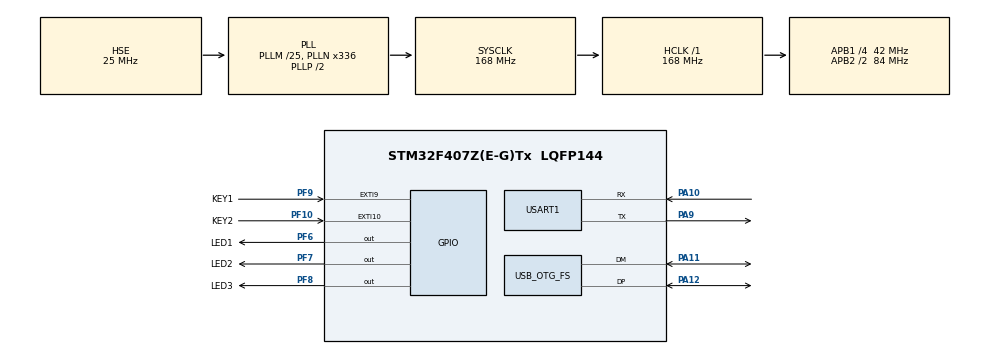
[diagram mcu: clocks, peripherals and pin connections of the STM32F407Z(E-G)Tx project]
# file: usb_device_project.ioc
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Mcu.Family=STM32F4
Mcu.Name=STM32F407Z(E-G)Tx
Mcu.Package=LQFP144
NVIC.EXTI15_10_IRQn=true\:0\:0\:false\:false\:true\:true\:true\:true
NVIC.EXTI9_5_IRQn=true\:0\:0\:false\:false\:true\:true\:true\:true
NVIC.OTG_FS_IRQn=true\:0\:0\:false\:false\:true\:false\:true\:true
NVIC.PriorityGroup=NVIC_PRIORITYGROUP_4
PA10.Mode=Asynchronous
PA10.Signal=USART1_RX
PA11.Mode=Device_Only
PA11.Signal=USB_OTG_FS_DM
PA12.Mode=Device_Only
PA12.Signal=USB_OTG_FS_DP
PA9.Mode=Asynchronous
PA9.Signal=USART1_TX
PF10.GPIO_Label=KEY2
PF10.GPIO_ModeDefaultEXTI=GPIO_MODE_IT_RISING_FALLING
PF10.GPIO_PuPd=GPIO_PULLUP
PF10.Signal=GPXTI10
PF6.GPIO_Label=LED1
PF6.PinState=GPIO_PIN_SET
PF6.Signal=GPIO_Output
PF7.GPIO_Label=LED2
PF7.PinState=GPIO_PIN_SET
PF7.Signal=GPIO_Output
PF8.GPIO_Label=LED3
PF8.PinState=GPIO_PIN_SET
PF8.Signal=GPIO_Output
PF9.GPIO_Label=KEY1
PF9.GPIO_ModeDefaultEXTI=GPIO_MODE_IT_RISING_FALLING
PF9.GPIO_PuPd=GPIO_PULLUP
PF9.Signal=GPXTI9
PH0-OSC_IN.Mode=HSE-External-Oscillator
PH0-OSC_IN.Signal=RCC_OSC_IN
PH1-OSC_OUT.Mode=HSE-External-Oscillator
PH1-OSC_OUT.Signal=RCC_OSC_OUT
ProjectManager.HeapSize=0x200
ProjectManager.StackSize=0x400
ProjectManager.TargetToolchain=STM32CubeIDE
RCC.48MHZClocksFreq_Value=48000000
RCC.AHBFreq_Value=168000000
RCC.APB1CLKDivider=RCC_HCLK_DIV4
RCC.APB1Freq_Value=42000000
RCC.APB1TimFreq_Value=84000000
RCC.APB2CLKDivider=RCC_HCLK_DIV2
RCC.APB2Freq_Value=84000000
RCC.APB2TimFreq_Value=168000000
RCC.CortexFreq_Value=168000000
RCC.HCLKFreq_Value=168000000
RCC.HSE_VALUE=25000000
RCC.HSI_VALUE=16000000
RCC.LSE_VALUE=32768
RCC.PLLM=25
RCC.PLLN=336
RCC.PLLQ=7
RCC.SYSCLKFreq_VALUE=168000000
RCC.SYSCLKSource=RCC_SYSCLKSOURCE_PLLCLK
RCC.VCOOutputFreq_Value=336000000
USART1.VirtualMode=VM_ASYNC
USB_DEVICE.CLASS_NAME_FS=CUSTOM_HID
USB_DEVICE.USBD_CUSTOMHID_OUTREPORT_BUF_SIZE-CUSTOM_HID_FS=2
USB_DEVICE.USBD_CUSTOM_HID_REPORT_DESC_SIZE-CUSTOM_HID_FS=163
USB_DEVICE.VirtualMode-CUSTOM_HID_FS=CustomHid
USB_DEVICE.VirtualModeFS=Custom_Hid_FS
USB_OTG_FS.VirtualMode=Device_Only
VP_USB_DEVICE_VS_USB_DEVICE_CUSTOM_HID_FS.Mode=CUSTOM_HID_FS
board=custom

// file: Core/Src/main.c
/* USER CODE BEGIN Header */
/**
  ******************************************************************************
  * @file           : main.c
  * @brief          : Main program body
  ******************************************************************************
  * @attention
  *
  * Copyright (c) 2026 STMicroelectronics.
  * All rights reserved.
  *
  * This software is licensed under terms that can be found in the LICENSE file
  * in the root directory of this software component.
  * If no LICENSE file comes with this software, it is provided AS-IS.
  *
  ******************************************************************************
  */
/* USER CODE END Header */
#include "main.h"
#include "usb_device.h"

UART_HandleTypeDef huart1;

void SystemClock_Config(void);
static void MX_GPIO_Init(void);
static void MX_USART1_UART_Init(void);

/* USER CODE BEGIN 0 */
#define hUART           huart1
int _write( int32_t file , uint8_t *ptr , int32_t len )
{
    /* Implement your write code here, this is used by puts and printf for example */
    for ( int16_t i = 0 ; i < len ; ++i )
    {
        HAL_UART_Transmit( &hUART, ptr++, 1, 100);
    }
    return len;
}
/* USER CODE END 0 */

int main(void)
{

  /* MCU Configuration--------------------------------------------------------*/

  /* Reset of all peripherals, Initializes the Flash interface and the Systick. */
  HAL_Init();

  /* Configure the system clock */
  SystemClock_Config();

  /* Initialize all configured peripherals */
  MX_GPIO_Init();
  MX_USART1_UART_Init();
  MX_USB_DEVICE_Init();

  /* Infinite loop */
  while (1)
  {

  }
}

void SystemClock_Config(void)
{
  RCC_OscInitTypeDef RCC_OscInitStruct = {0};
  RCC_ClkInitTypeDef RCC_ClkInitStruct = {0};

  /** Configure the main internal regulator output voltage
  */
  __HAL_RCC_PWR_CLK_ENABLE();
  __HAL_PWR_VOLTAGESCALING_CONFIG(PWR_REGULATOR_VOLTAGE_SCALE1);

  /** Initializes the RCC Oscillators according to the specified parameters
  * in the RCC_OscInitTypeDef structure.
  */
  RCC_OscInitStruct.OscillatorType = RCC_OSCILLATORTYPE_HSE;
  RCC_OscInitStruct.HSEState = RCC_HSE_ON;
  RCC_OscInitStruct.PLL.PLLState = RCC_PLL_ON;
  RCC_OscInitStruct.PLL.PLLSource = RCC_PLLSOURCE_HSE;
  RCC_OscInitStruct.PLL.PLLM = 25;
  RCC_OscInitStruct.PLL.PLLN = 336;
  RCC_OscInitStruct.PLL.PLLP = RCC_PLLP_DIV2;
  RCC_OscInitStruct.PLL.PLLQ = 7;
  if (HAL_RCC_OscConfig(&RCC_OscInitStruct) != HAL_OK)
  {
    Error_Handler();
  }

  /** Initializes the CPU, AHB and APB buses clocks
  */
  RCC_ClkInitStruct.ClockType = RCC_CLOCKTYPE_HCLK|RCC_CLOCKTYPE_SYSCLK
                              |RCC_CLOCKTYPE_PCLK1|RCC_CLOCKTYPE_PCLK2;
  RCC_ClkInitStruct.SYSCLKSource = RCC_SYSCLKSOURCE_PLLCLK;
  RCC_ClkInitStruct.AHBCLKDivider = RCC_SYSCLK_DIV1;
  RCC_ClkInitStruct.APB1CLKDivider = RCC_HCLK_DIV4;
  RCC_ClkInitStruct.APB2CLKDivider = RCC_HCLK_DIV2;

  if (HAL_RCC_ClockConfig(&RCC_ClkInitStruct, FLASH_LATENCY_5) != HAL_OK)
  {
    Error_Handler();
  }
}

static void MX_USART1_UART_Init(void)
{

  huart1.Instance = USART1;
  huart1.Init.BaudRate = 115200;
  huart1.Init.WordLength = UART_WORDLENGTH_8B;
  huart1.Init.StopBits = UART_STOPBITS_1;
  huart1.Init.Parity = UART_PARITY_NONE;
  huart1.Init.Mode = UART_MODE_TX_RX;
  huart1.Init.HwFlowCtl = UART_HWCONTROL_NONE;
  huart1.Init.OverSampling = UART_OVERSAMPLING_16;
  if (HAL_UART_Init(&huart1) != HAL_OK)
  {
    Error_Handler();
  }

}

static void MX_GPIO_Init(void)
{
  GPIO_InitTypeDef GPIO_InitStruct = {0};

  /* GPIO Ports Clock Enable */
  __HAL_RCC_GPIOF_CLK_ENABLE();
  __HAL_RCC_GPIOH_CLK_ENABLE();
  __HAL_RCC_GPIOA_CLK_ENABLE();

  /*Configure GPIO pin Output Level */
  HAL_GPIO_WritePin(GPIOF, LED1_Pin|LED2_Pin|LED3_Pin, GPIO_PIN_SET);

  /*Configure GPIO pins : LED1_Pin LED2_Pin LED3_Pin */
  GPIO_InitStruct.Pin = LED1_Pin|LED2_Pin|LED3_Pin;
  GPIO_InitStruct.Mode = GPIO_MODE_OUTPUT_PP;
  GPIO_InitStruct.Pull = GPIO_NOPULL;
  GPIO_InitStruct.Speed = GPIO_SPEED_FREQ_LOW;
  HAL_GPIO_Init(GPIOF, &GPIO_InitStruct);

  /*Configure GPIO pins : KEY1_Pin KEY2_Pin */
  GPIO_InitStruct.Pin = KEY1_Pin|KEY2_Pin;
  GPIO_InitStruct.Mode = GPIO_MODE_IT_RISING_FALLING;
  GPIO_InitStruct.Pull = GPIO_PULLUP;
  HAL_GPIO_Init(GPIOF, &GPIO_InitStruct);

  /* EXTI interrupt init*/
  HAL_NVIC_SetPriority(EXTI9_5_IRQn, 0, 0);
  HAL_NVIC_EnableIRQ(EXTI9_5_IRQn);

  HAL_NVIC_SetPriority(EXTI15_10_IRQn, 0, 0);
  HAL_NVIC_EnableIRQ(EXTI15_10_IRQn);

}

void Error_Handler(void)
{
  __disable_irq();
  while (1)
  {
  }
}
